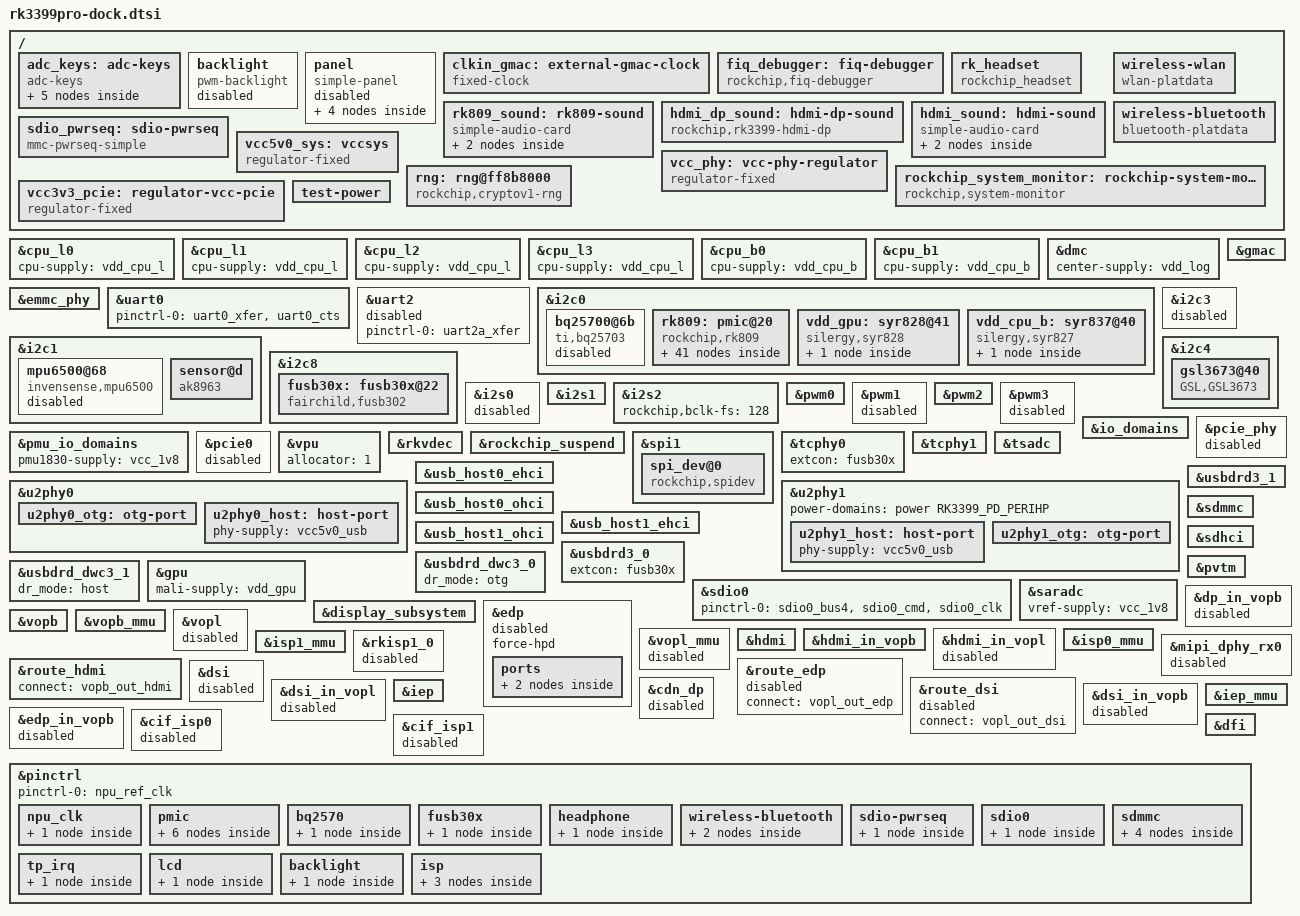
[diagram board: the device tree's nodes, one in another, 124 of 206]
// SPDX-License-Identifier: (GPL-2.0+ OR MIT)
// Copyright (c) 2018 Fuzhou Rockchip Electronics Co., Ltd

#include <dt-bindings/gpio/gpio.h>
#include <dt-bindings/pinctrl/rockchip.h>
#include <dt-bindings/input/input.h>
#include <dt-bindings/display/drm_mipi_dsi.h>
#include <dt-bindings/sensor-dev.h>
#include <dt-bindings/pwm/pwm.h>
#include "rk3399-vop-clk-set.dtsi"

/ {

	adc_keys: adc-keys {
		compatible = "adc-keys";
		io-channels = <&saradc 2>;
		io-channel-names = "buttons";
		poll-interval = <100>;
		keyup-threshold-microvolt = <1800000>;

		esc-key {
			linux,code = <KEY_ESC>;
			label = "esc";
			press-threshold-microvolt = <1310000>;
		};

		menu-key {
			linux,code = <KEY_MENU>;
			label = "menu";
			press-threshold-microvolt = <987000>;
		};

		home-key {
			linux,code = <KEY_HOME>;
			label = "home";
			press-threshold-microvolt = <624000>;
		};

		vol-down-key {
			linux,code = <KEY_VOLUMEDOWN>;
			label = "volume down";
			press-threshold-microvolt = <300000>;
		};

		vol-up-key {
			linux,code = <KEY_VOLUMEUP>;
			label = "volume up";
			press-threshold-microvolt = <17000>;
		};
	};

	backlight: backlight {
		status = "disabled";
		compatible = "pwm-backlight";
		pwms = <&pwm0 0 25000 0>;
		brightness-levels = <
			  0  20  20  21  21  22  22  23
			 23  24  24  25  25  26  26  27
			 27  28  28  29  29  30  30  31
			 31  32  32  33  33  34  34  35
			 35  36  36  37  37  38  38  39
			 40  41  42  43  44  45  46  47
			 48  49  50  51  52  53  54  55
			 56  57  58  59  60  61  62  63
			 64  65  66  67  68  69  70  71
			 72  73  74  75  76  77  78  79
			 80  81  82  83  84  85  86  87
			 88  89  90  91  92  93  94  95
			 96  97  98  99 100 101 102 103
			104 105 106 107 108 109 110 111
			112 113 114 115 116 117 118 119
			120 121 122 123 124 125 126 127
			128 129 130 131 132 133 134 135
			136 137 138 139 140 141 142 143
			144 145 146 147 148 149 150 151
			152 153 154 155 156 157 158 159
			160 161 162 163 164 165 166 167
			168 169 170 171 172 173 174 175
			176 177 178 179 180 181 182 183
			184 185 186 187 188 189 190 191
			192 193 194 195 196 197 198 199
			200 201 202 203 204 205 206 207
			208 209 210 211 212 213 214 215
			216 217 218 219 220 221 222 223
			224 225 226 227 228 229 230 231
			232 233 234 235 236 237 238 239
			240 241 242 243 244 245 246 247
			248 249 250 251 252 253 254 255
		>;
		default-brightness-level = <10>;
		pinctrl-names = "default";
		pinctrl-0 = <&bl_en>;
		enable-gpios = <&gpio1 RK_PB5 GPIO_ACTIVE_HIGH>;
	};

	panel: panel {
		status = "disabled";
		compatible = "simple-panel";
		backlight = <&backlight>;
		enable-gpios = <&gpio4 RK_PD6 GPIO_ACTIVE_HIGH>;
		prepare-delay-ms = <20>;
		enable-delay-ms = <20>;
		reset-delay-ms = <20>;

		display-timings {
			native-mode = <&timing0>;
			timing0: timing0 {
				clock-frequency = <65000000>;
				hactive = <1280>;
				vactive = <800>;
				hfront-porch = <28>;
				hsync-len = <16>;
				hback-porch = <16>;
				vfront-porch = <6>;
				vsync-len = <2>;
				vback-porch = <4>;
				hsync-active = <0>;
				vsync-active = <0>;
				de-active = <0>;
				pixelclk-active = <0>;
			};
		};

		ports {
			panel_in: endpoint {
				remote-endpoint = <&edp_out>;
			};
		};
	};

	clkin_gmac: external-gmac-clock {
		compatible = "fixed-clock";
		clock-frequency = <125000000>;
		clock-output-names = "clkin_gmac";
		#clock-cells = <0>;
	};

	fiq_debugger: fiq-debugger {
		compatible = "rockchip,fiq-debugger";
		rockchip,serial-id = <2>;
		rockchip,wake-irq = <0>;
		rockchip,irq-mode-enable = <1>;  /* If enable uart uses irq instead of fiq */
		rockchip,baudrate = <1500000>;  /* Only 115200 and 1500000 */
		pinctrl-names = "default";
		pinctrl-0 = <&uart2a_xfer>;
		interrupts = <GIC_SPI 150 IRQ_TYPE_LEVEL_HIGH 0>;
		status = "okay";
	};

	rk_headset {
		status = "okay";
		compatible = "rockchip_headset";
		headset_gpio = <&gpio0 RK_PB5 GPIO_ACTIVE_LOW>;	
		pinctrl-names = "default";
		pinctrl-0 = <&hp_det>;
		io-channels = <&saradc 3>;
	};

	rk809_sound: rk809-sound {
		compatible = "simple-audio-card";
		simple-audio-card,format = "i2s";
		simple-audio-card,name = "rockchip,rk809-codec";
		simple-audio-card,mclk-fs = <256>;
		simple-audio-card,widgets =
			"Microphone", "Mic Jack",
			"Headphone", "Headphone Jack";
		simple-audio-card,routing =
			"Mic Jack", "MICBIAS1",
			"IN1P", "Mic Jack",
			"Headphone Jack", "HPOL",
			"Headphone Jack", "HPOR";
		simple-audio-card,cpu {
			sound-dai = <&i2s1>;
		};
		simple-audio-card,codec {
			sound-dai = <&rk809_codec>;
		};
	};

	hdmi_dp_sound: hdmi-dp-sound {
		compatible = "rockchip,rk3399-hdmi-dp";
		rockchip,codec = <&hdmi &cdn_dp>;
		rockchip,cpu = <&i2s2>;
		status = "okay";
	};

	hdmi_sound: hdmi-sound {
		status = "okay";
		compatible = "simple-audio-card";
		simple-audio-card,format = "i2s";
		simple-audio-card,mclk-fs = <256>;
		simple-audio-card,name = "HDMI-CODEC";

		simple-audio-card,cpu {
			sound-dai = <&i2s2>;
		};

		simple-audio-card,codec {
			sound-dai = <&hdmi>;
		};
	};

	wireless-wlan {
		WIFI,host_wake_irq = <&gpio0 RK_PA3 GPIO_ACTIVE_HIGH>;
		compatible = "wlan-platdata";
		rockchip,grf = <&grf>;
		sdio_vref = <1800>;
		status = "okay";
		wifi_chip_type = "ap6354";
	};

	wireless-bluetooth {
		BT,reset_gpio = <&gpio2 RK_PD4 GPIO_ACTIVE_HIGH>;
		BT,wake_gpio = <&gpio2 RK_PD2 GPIO_ACTIVE_HIGH>;
		BT,wake_host_irq = <&gpio0 RK_PA5 GPIO_ACTIVE_HIGH>;
		//BT,power_gpio = <&gpio2 RK_PD4 GPIO_ACTIVE_HIGH>;
		clock-names = "ext_clock";
		clocks = <&rk809 0x01>;
		compatible = "bluetooth-platdata";
		pinctrl-0 = <&uart0_rts &bt_irq_gpio>;
		//pinctrl-0 = <&uart0_rts>;
		pinctrl-1 = <&uart0_gpios>;
		pinctrl-names = "default","rts_gpio";
		status = "okay";
		uart_rts_gpios = <&gpio2 19 GPIO_ACTIVE_LOW>;
	};

	sdio_pwrseq: sdio-pwrseq {
		status = "okay";
		compatible = "mmc-pwrseq-simple";
		clocks = <&rk809 0x01>;
		clock-names = "ext_clock";
		pinctrl-names = "default";
		pinctrl-0 = <&wifi_enable_h>;
		reset-gpios = <&gpio2 RK_PD3 GPIO_ACTIVE_LOW>;
	};

	vcc_phy: vcc-phy-regulator {
		compatible = "regulator-fixed";
		regulator-name = "vcc_phy";
		regulator-always-on;
		regulator-boot-on;
	};

	vcc5v0_sys: vccsys {
		compatible = "regulator-fixed";
		regulator-name = "vcc5v0_sys";
		regulator-always-on;
		regulator-boot-on;
		regulator-min-microvolt = <5000000>;
		regulator-max-microvolt = <5000000>;
	};

	rockchip_system_monitor: rockchip-system-monitor {
		compatible = "rockchip,system-monitor";
		rockchip,polling-delay = <200>;
		rockchip,thermal-zone = "soc-thermal";
	};

	vcc3v3_pcie: regulator-vcc-pcie {
		compatible = "regulator-fixed";
		enable-active-high;
		gpio = <&gpio4 RK_PD4 GPIO_ACTIVE_HIGH>;
		//pinctrl-names = "default";
		//pinctrl-0 = <&pcie_pwr>;
		regulator-name = "vcc3v3_pcie";
		regulator-always-on;
		regulator-boot-on;
		vin-supply = <&vcc5v0_sys>;
	};

	rng: rng@ff8b8000 {
		compatible = "rockchip,cryptov1-rng";
		reg = <0x0 0xff8b8000 0x0 0x1000>;
		clocks = <&cru SCLK_CRYPTO1>, <&cru HCLK_S_CRYPTO1>;
		clock-names = "clk_crypto", "hclk_crypto";
		assigned-clocks = <&cru SCLK_CRYPTO1>, <&cru HCLK_S_CRYPTO1>;
		assigned-clock-rates = <150000000>, <100000000>;
		status = "disabled";
	};

	test-power {
		status = "okay";
	};
};

&cpu_l0 {
	cpu-supply = <&vdd_cpu_l>;
};

&cpu_l1 {
	cpu-supply = <&vdd_cpu_l>;
};

&cpu_l2 {
	cpu-supply = <&vdd_cpu_l>;
};

&cpu_l3 {
	cpu-supply = <&vdd_cpu_l>;
};

&cpu_b0 {
	cpu-supply = <&vdd_cpu_b>;
};

&cpu_b1 {
	cpu-supply = <&vdd_cpu_b>;
};

&dmc {
	status = "okay";
	//pvtm = <&pvtm>;
	center-supply = <&vdd_log>;
};

&emmc_phy {
	status = "okay";
};

&gmac {
	assigned-clock-parents = <&clkin_gmac>;
	assigned-clocks = <&cru SCLK_RMII_SRC>;
	phy-supply = <&vcc_phy>;
	phy-mode = "rgmii";
	clock_in_out = "input";
	snps,reset-gpio = <&gpio3 RK_PB7 GPIO_ACTIVE_LOW>;
	snps,reset-active-low;
	snps,reset-delays-us = <0 10000 50000>;
	pinctrl-names = "default";
	pinctrl-0 = <&rgmii_pins>;
	tx_delay = <0x28>;
	rx_delay = <0x11>;
	status = "okay";
};

&uart0 {
	pinctrl-names = "default";
	pinctrl-0 = <&uart0_xfer &uart0_cts>;
	status = "okay";
};

&uart2 {
	pinctrl-0 = <&uart2a_xfer>;
	status = "disabled";
};

&i2c0 {
	status = "okay";
	i2c-scl-rising-time-ns = <180>;
	i2c-scl-falling-time-ns = <30>;
	clock-frequency = <400000>;

	bq25700@6b {
		compatible = "ti,bq25703";
		extcon = <&fusb30x>;
		//interrupt-parent = <0x33>;
		//interrupts = <0x01 0x08>;
		pd-charge-only = <0x00>;
		pinctrl-0 = <&charger_ok_int>;
		pinctrl-names = "default";
		reg = <0x6b>;
		status = "disabled";
		ti,charge-current = <0x16e360>;
		ti,input-current = <0x7a120>;
		ti,input-current-cdp = <0x1e8480>;
		ti,input-current-dc = <0x1e8480>;
		ti,input-current-dcp = <0x1e8480>;
		ti,input-current-sdp = <0x7a120>;
		ti,max-charge-voltage = <0x84d000>;
		ti,max-input-current = <0x5b8d80>;
		ti,max-input-voltage = <0x1312d00>;
		ti,minimum-sys-voltage = <0x663be0>;
		ti,otg-current = <0x7a120>;
		ti,otg-voltage = <0x4c4b40>;
	};

	rk809: pmic@20 {
		compatible = "rockchip,rk809";
		reg = <0x20>;

		interrupt-parent = <&gpio1>;
		interrupts = <RK_PC2 IRQ_TYPE_LEVEL_LOW>;
		pinctrl-names = "default", "pmic-sleep",
				"pmic-power-off", "pmic-reset";
		pinctrl-0 = <&pmic_int_l>;
		pinctrl-1 = <&soc_slppin_slp>, <&rk809_slppin_slp>;
		pinctrl-2 = <&soc_slppin_gpio>, <&rk809_slppin_pwrdn>;
		pinctrl-3 = <&soc_slppin_gpio>, <&rk809_slppin_null>;
		rockchip,system-power-controller;
		pmic-reset-func = <0>;
		wakeup-source;
		#clock-cells = <1>;
		clock-output-names = "rk808-clkout1", "rk808-clkout2";

		vcc1-supply = <&vcc5v0_sys>;
		vcc2-supply = <&vcc5v0_sys>;
		vcc3-supply = <&vcc5v0_sys>;
		vcc4-supply = <&vcc5v0_sys>;
		vcc5-supply = <&vcc_buck5>;
		vcc6-supply = <&vcc_buck5>;
		vcc7-supply = <&vcc3v3_sys>;
		vcc8-supply = <&vcc3v3_sys>;
		vcc9-supply = <&vcc5v0_sys>;

		pwrkey {
			status = "okay";
		};

		rk809_rtc: rtc {
			status = "okay";
		};

		pinctrl_rk8xx: pinctrl_rk8xx {
			gpio-controller;
			#gpio-cells = <2>;

			rk809_slppin_null: rk809_slppin_null {
				pins = "gpio_slp";
				function = "pin_fun0";
			};

			rk809_slppin_slp: rk809_slppin_slp {
				pins = "gpio_slp";
				function = "pin_fun1";
			};

			rk809_slppin_pwrdn: rk809_slppin_pwrdn {
				pins = "gpio_slp";
				function = "pin_fun2";
			};

			rk809_slppin_rst: rk809_slppin_rst {
				pins = "gpio_slp";
				function = "pin_fun3";
			};
		};

		regulators {
			vdd_log: DCDC_REG1 {
				regulator-always-on;
				regulator-boot-on;
				regulator-min-microvolt = <750000>;
				regulator-max-microvolt = <1350000>;
				regulator-initial-mode = <2>;
				regulator-name = "vdd_log";
				regulator-state-mem {
					regulator-off-in-suspend;
					regulator-suspend-microvolt = <900000>;
				};
			};

			vdd_cpu_l: DCDC_REG2 {
				regulator-always-on;
				regulator-boot-on;
				regulator-min-microvolt = <750000>;
				regulator-max-microvolt = <1350000>;
				regulator-ramp-delay = <6001>;
				regulator-initial-mode = <2>;
				regulator-name = "vdd_cpu_l";
				regulator-state-mem {
					regulator-off-in-suspend;
				};
			};

			vcc_ddr: DCDC_REG3 {
				regulator-always-on;
				regulator-boot-on;
				regulator-name = "vcc_ddr";
				regulator-initial-mode = <2>;
				regulator-state-mem {
					regulator-on-in-suspend;
				};
			};

			vcc3v3_sys: DCDC_REG4 {
				regulator-always-on;
				regulator-boot-on;
				regulator-min-microvolt = <3300000>;
				regulator-max-microvolt = <3300000>;
				regulator-initial-mode = <2>;
				regulator-name = "vcc3v3_sys";
				regulator-state-mem {
					regulator-on-in-suspend;
					regulator-suspend-microvolt = <3300000>;
				};
			};

			vcc_buck5: DCDC_REG5 {
				regulator-always-on;
				regulator-boot-on;
				regulator-min-microvolt = <2200000>;
				regulator-max-microvolt = <2200000>;
				regulator-name = "vcc_buck5";
				regulator-state-mem {
					regulator-on-in-suspend;
					regulator-suspend-microvolt = <2200000>;
				};
			};

			vcca_0v9: LDO_REG1 {
				regulator-always-on;
				regulator-boot-on;
				regulator-min-microvolt = <900000>;
				regulator-max-microvolt = <900000>;
				regulator-name = "vcca_0v9";
				regulator-state-mem {
					regulator-off-in-suspend;
				};
			};

			vcc_1v8: LDO_REG2 {
				regulator-always-on;
				regulator-boot-on;
				regulator-min-microvolt = <1800000>;
				regulator-max-microvolt = <1800000>;

				regulator-name = "vcc_1v8";
				regulator-state-mem {
					regulator-on-in-suspend;
					regulator-suspend-microvolt = <1800000>;
				};
			};

			vcc0v9_soc: LDO_REG3 {
				regulator-always-on;
				regulator-boot-on;
				regulator-min-microvolt = <900000>;
				regulator-max-microvolt = <900000>;

				regulator-name = "vcc0v9_soc";
				regulator-state-mem {
					regulator-on-in-suspend;
					regulator-suspend-microvolt = <900000>;
				};
			};

			vcca_1v8: LDO_REG4 {
				regulator-always-on;
				regulator-boot-on;
				regulator-min-microvolt = <1800000>;
				regulator-max-microvolt = <1800000>;

				regulator-name = "vcca_1v8";
				regulator-state-mem {
					regulator-off-in-suspend;
				};
			};

			vdd1v5_dvp: LDO_REG5 {
				regulator-always-on;
				regulator-boot-on;
				regulator-min-microvolt = <1500000>;
				regulator-max-microvolt = <1500000>;

				regulator-name = "vdd1v5_dvp";
				regulator-state-mem {
					regulator-off-in-suspend;
				};
			};

			vcc_1v5: LDO_REG6 {
				regulator-always-on;
				regulator-boot-on;
				regulator-min-microvolt = <1500000>;
				regulator-max-microvolt = <1500000>;

				regulator-name = "vcc_1v5";
				regulator-state-mem {
					regulator-off-in-suspend;
				};
			};

			vcc_3v0: LDO_REG7 {
				regulator-always-on;
				regulator-boot-on;
				regulator-min-microvolt = <3000000>;
				regulator-max-microvolt = <3000000>;

				regulator-name = "vcc_3v0";
				regulator-state-mem {
					regulator-off-in-suspend;
				};
			};

			vccio_sd: LDO_REG8 {
				regulator-always-on;
				regulator-boot-on;
				regulator-min-microvolt = <1800000>;
				regulator-max-microvolt = <3300000>;

				regulator-name = "vccio_sd";
				regulator-state-mem {
					regulator-off-in-suspend;
				};
			};

			vcc_sd: LDO_REG9 {
				regulator-always-on;
				regulator-boot-on;
				regulator-min-microvolt = <3300000>;
				regulator-max-microvolt = <3300000>;

				regulator-name = "vcc_sd";
				regulator-state-mem {
					regulator-off-in-suspend;
				};
			};

			vcc5v0_usb: SWITCH_REG1 {
				regulator-min-microvolt = <5000000>;
				regulator-max-microvolt = <5000000>;
				regulator-always-on;
				regulator-boot-on;
				regulator-name = "vcc5v0_usb";
				regulator-state-mem {
					regulator-on-in-suspend;
					regulator-suspend-microvolt = <5000000>;
				};
			};

			vccio_3v3: SWITCH_REG2 {
				regulator-always-on;
				regulator-boot-on;
				regulator-min-microvolt = <3300000>;
				regulator-max-microvolt = <3300000>;

				regulator-name = "vccio_3v3";
				regulator-state-mem {
					regulator-off-in-suspend;
				};
			};
		};

		rk809_codec: codec {
			#sound-dai-cells = <0>;
			compatible = "rockchip,rk809-codec", "rockchip,rk817-codec";
			clocks = <&cru SCLK_I2S_8CH_OUT>;
			clock-names = "mclk";
			pinctrl-names = "default";
			pinctrl-0 = <&i2s_8ch_mclk>;
			hp-volume = <20>;
			spk-volume = <3>;
			capture-volume = <0>;
			//mic-in-differential;
			status = "okay";
		};
	};

	vdd_gpu: syr828@41 {
		compatible = "silergy,syr828";
		fcs,suspend-voltage-selector = <1>;
		//phandle = <0xa4>;
		pinctrl-0 = <&vsel2_gpio>;
		reg = <0x41>;
		regulator-always-on;
		regulator-boot-on;
		regulator-compatible = "fan53555-reg";
		regulator-max-microvolt = <1400000>;
		regulator-min-microvolt = <735000>;
		regulator-name = "vdd_gpu";
		regulator-ramp-delay = <1000>;
		status = "okay";
		vin-supply = <&vcc5v0_sys>;
		vsel-gpios = <&gpio1 RK_PB6 GPIO_ACTIVE_HIGH>;

		regulator-state-mem {
			regulator-off-in-suspend;
		};
	};

	vdd_cpu_b: syr837@40 {
		compatible = "silergy,syr827";
		fcs,suspend-voltage-selector = <1>;
		//phandle = <0x12>;
		pinctrl-0 = <&vsel1_gpio>;
		reg = <0x40>;
		regulator-always-on;
		regulator-boot-on;
		regulator-compatible = "fan53555-reg";
		regulator-initial-state = <3>;
		regulator-max-microvolt = <1500000>;
		regulator-min-microvolt = <712500>;
		regulator-name = "vdd_cpu_b";
		regulator-ramp-delay = <1000>;
		vin-supply = <&vcc5v0_sys>;
		vsel-gpios = <&gpio1 RK_PC1 GPIO_ACTIVE_HIGH>;

		regulator-state-mem {
			regulator-off-in-suspend;
		};
	};
};

&i2c1 {
	status = "okay";
	i2c-scl-rising-time-ns = <140>;
	i2c-scl-falling-time-ns = <30>;	
	mpu6500@68 {
		status = "disabled";
		compatible = "invensense,mpu6500";
		reg = <0x68>;
		irq-gpio = <&gpio3 RK_PD2 IRQ_TYPE_EDGE_RISING>;
		mpu-int_config = <0x10>;
		mpu-level_shifter = <0>;
		mpu-orientation = <0 1 0 1 0 0 0 0 1>;
		orientation-x= <0>;
		orientation-y= <0>;
		orientation-z= <1>;
		mpu-debug = <1>;
	};

	sensor@d {
		status = "okay";
		compatible = "ak8963";
		reg = <0x0d>;
		type = <SENSOR_TYPE_COMPASS>;
		irq-gpio = <&gpio3 RK_PD7 IRQ_TYPE_EDGE_RISING>;
		irq_enable = <0>;
		poll_delay_ms = <30>;
		layout = <3>;
	};
};

&i2c3 {
	i2c-scl-rising-time-ns = <450>;
	i2c-scl-falling-time-ns = <15>;
	status = "disabled";
};

&i2c4 {
	status = "okay";
	i2c-scl-falling-time-ns = <11>;
	i2c-scl-rising-time-ns = <345>;
	gsl3673@40 {
		compatible = "GSL,GSL3673";
		irq_gpio_number = <&gpio4 19 8>;
		reg = <0x40>;
		rst_gpio_number = <&gpio4 22 GPIO_ACTIVE_HIGH>;
		screen_max_x = <0x600>;
		screen_max_y = <0x800>;
	};
};

&i2c8 {
	status = "okay";
	i2c-scl-falling-time-ns = <11>;
	i2c-scl-rising-time-ns = <345>;
	clock-frequency = <100000>;
	status = "okay";

	fusb30x: fusb30x@22 {
		compatible = "fairchild,fusb302";
		int-n-gpios = <&gpio1 0x02 0x00>;
		//phandle = <0x28>;
		pinctrl-0 = <&fusb0_int>;
		pinctrl-names = "default";
		reg = <0x22>;
		status = "okay";
		//fusb302,role = "ROLE_MODE_DRP";
		//fusb302,try_role = "ROLE_MODE_DFP";
	};
	
};

&i2s0 {
	#sound-dai-cells = <0>;
	status = "dsiabled";
};

&i2s1 {
	status = "okay";
	#sound-dai-cells = <0>;
};
&i2s2 {
	#sound-dai-cells = <0>;
	rockchip,bclk-fs = <128>;
	status = "okay";
};

&pwm0 {
	status = "okay";
};

&pwm1 {
	status = "disabled";
};

&pwm2 {
	status = "okay";
};

&pwm3 {
	status = "disabled";
};

&io_domains {
	status = "okay";
	bt656-supply = <&vcca_1v8>;
	audio-supply = <&vcca_1v8>;
	sdmmc-supply = <&vccio_sd>;
	gpio1830-supply = <&vcc_3v0>;
};

&pmu_io_domains {
	status = "okay";
	pmu1830-supply = <&vcc_1v8>;
};

&pcie_phy {
	status = "disabled";
};

&pcie0 {
	status = "disabled";
	vpcie0v9-supply = <&vcca_0v9>;	/* VCC_0V9_S0 */
	vpcie1v8-supply = <&vcca_1v8>;	/* VCC_1V8_S0 */
	vpcie3v3-supply = <&vcc3v3_pcie>;
};

&vpu {
	status = "okay";
	allocator = <1>;
	//vcodec-supply = <&vdd_log>;
	/* 0 means ion, 1 means drm */
	//allocator = <0>;
};

&rkvdec {
	status = "okay";
	//vcodec-supply = <&vdd_log>;
	/* 0 means ion, 1 means drm */
	//allocator = <0>;
};

&rockchip_suspend {
	status = "okay";
	rockchip,sleep-debug-en = <1>;
	rockchip,sleep-mode-config = <
		(0
		| RKPM_SLP_ARMPD
		| RKPM_SLP_PERILPPD
		| RKPM_SLP_DDR_RET
		| RKPM_SLP_PLLPD
		| RKPM_SLP_CENTER_PD
		| RKPM_SLP_OSC_DIS
		| RKPM_SLP_AP_PWROFF
		)
	>;
	rockchip,wakeup-config = <
		(0
		| RKPM_GPIO_WKUP_EN
		| RKPM_USB_WKUP_EN
		| RKPM_USB_LINESTATE_WKUP_EN
		)
	>;

	rockchip,pwm-regulator-config = <
		(0
		| PWM2_REGULATOR_EN
		)
	>;	
	rockchip,power-ctrl =
		<&gpio1 RK_PC1 GPIO_ACTIVE_HIGH>,
		<&gpio1 RK_PB6 GPIO_ACTIVE_HIGH>;
};

&spi1 {
	status = "okay";
	dma-names = "tx", "rx";
	dmas = <&dmac_peri 12>, <&dmac_peri 13>;
	max-freq = <48000000>; /* spi internal clk, don't modify */
	spi_dev@0 {
		compatible = "rockchip,spidev";
		reg = <0>;
		spi-max-frequency = <12000000>;
		spi-lsb-first;
		status = "okay";
	};
};

&tcphy0 {
	extcon = <&fusb30x>;
	status = "okay";
};

&tcphy1 {
	status = "okay";
};

&tsadc {
	rockchip,hw-tshut-mode = <1>; /* tshut mode 0:CRU 1:GPIO */
	rockchip,hw-tshut-polarity = <1>; /* tshut polarity 0:LOW 1:HIGH */
	rockchip,hw-tshut-temp = <120000>;
	status = "okay";
};

&u2phy0 {
	status = "okay";
	extcon = <&fusb30x>;
	power-domains = <&power RK3399_PD_PERIHP>;
	u2phy0_otg: otg-port {
		status = "okay";
	};

	u2phy0_host: host-port {
		phy-supply = <&vcc5v0_usb>;
		status = "okay";
	};
};

&u2phy1 {
	status = "okay";
	power-domains = <&power RK3399_PD_PERIHP>;
	u2phy1_host: host-port {
		phy-supply = <&vcc5v0_usb>;
		status = "okay";
	};

	u2phy1_otg: otg-port {
		status = "okay";
	};
};

&usb_host0_ehci {
	status = "okay";
};

&usb_host0_ohci {
	status = "okay";
};

&usb_host1_ehci {
	status = "okay";
};

&usb_host1_ohci {
	status = "okay";
};

&usbdrd3_0 {
	extcon = <&fusb30x>;
	status = "okay";
};

&usbdrd_dwc3_0 {
	dr_mode = "otg";
	status = "okay";
};

&usbdrd3_1 {
	status = "okay";
};

&usbdrd_dwc3_1 {
	dr_mode = "host";
	status = "okay";
};

&sdio0 {
	status = "okay";
	pinctrl-0 = <&sdio0_bus4 &sdio0_cmd &sdio0_clk>;
};

&sdmmc {
	status = "okay";
	sd-uhs-sdr12;
	sd-uhs-sdr25;
	sd-uhs-sdr50;
	sd-uhs-sdr104;
	//vmmc-supply = <&vcc_sd>
};

&sdhci {
	status = "okay";
};

&gpu {
	status = "okay";
	mali-supply = <&vdd_gpu>;
};

&vpu {
	status = "okay";
	/* 0 means ion, 1 means drm */
	//allocator = <0>;
};

&pvtm {
	status = "okay";
};
/*
&power {
	pd_vi-supply = <&vdd_log>;
	pd_vpu-supply = <&vdd_log>;
	pd_gpu-supply = <&vdd_log>;
	pd_usb-supply = <&vcc5v0_usb>;
	pd_vo-supply = <&vdd_log>;
	pd_vopb-supply = <&vdd_log>;
	pd_vopl-supply = <&vdd_log>;
};
 */

&saradc {
	status = "okay";
	vref-supply = <&vcc_1v8>;
};

&display_subsystem {
	status = "okay";
};

&dp_in_vopb {
	status = "disabled";
};

&edp {
	status = "disabled";
	force-hpd;
	ports {
		port@1 {
			reg = <1>;
			edp_out: endpoint {
				remote-endpoint = <&panel_in>;
			};
		};
	};
};

&vopb {
	status = "okay";
	assigned-clocks = <&cru DCLK_VOP0_DIV>;
	assigned-clock-parents = <&cru PLL_VPLL>;
	rockchip,grf = <&grf>;
};

&vopb_mmu {
	status = "okay";
};

&vopl {
	status = "disabled";
	assigned-clocks = <&cru DCLK_VOP1_DIV>;
	assigned-clock-parents = <&cru PLL_CPLL>;
	rockchip,grf = <&grf>;
};

&vopl_mmu {
	status = "disabled";
};

&hdmi {
	status = "okay";
	#address-cells = <1>;
	#size-cells = <0>;
	#sound-dai-cells = <0>;
	//ddc-i2c-bus = <&i2c3>;
	pinctrl-0 = <&hdmi_i2c_xfer &hdmi_cec>;
	ddc-i2c-scl-high-time-ns = <9625>;
	ddc-i2c-scl-low-time-ns = <10000>;
	rockchip,phy-table =
		<74250000  0x8009 0x0004 0x0272>,
		<165000000 0x802b 0x0004 0x0209>,
		<297000000 0x8039 0x0005 0x028d>,
		<594000000 0x8039 0x0000 0x00f6>,
		<000000000 0x0000 0x0000 0x0000>;
};

&hdmi_in_vopb {
	status = "okay";
};

&hdmi_in_vopl {
	status = "disabled";
};

&isp0_mmu {
	status = "okay";
};

&isp1_mmu {
	status = "okay";
};


&rkisp1_0 {
	status = "disabled";
};

&mipi_dphy_rx0 {
	status = "disabled";
};

&route_hdmi {
	status = "okay";
	connect = <&vopb_out_hdmi>;
};

&route_edp {
	connect = <&vopl_out_edp>;
	status = "disabled";
};
&route_dsi {
	connect = <&vopl_out_dsi>;
	status = "disabled";
};

&dsi {
	status = "disabled";
};

&dsi_in_vopl {
	status = "disabled";
};

&dsi_in_vopb {
	status = "disabled";
};

&dp_in_vopb {
	status = "disabled";
};

&edp_in_vopb {
	status = "disabled";
};

&cdn_dp {
	extcon = <&fusb30x>;
	phys=<&tcphy0_dp>;
	status="disabled";
};

&iep {
	status="okay";
};
&iep_mmu {
	status="okay";
};

&cif_isp0 {
	assigned-clock-parents = <&cru 0x05>;
	assigned-clock-rates = <800000000>;
	assigned-clocks = <&cru 0xb2>;
	pinctrl-names = "cif_clkout\0isp_dvp8bit0\0isp_mipi_fl\0isp_mipi_fl_prefl\0isp_flash_as_gpio\0isp_flash_as_trigger_out";
	pinctrl-0 = <&cif_clkout>;
	pinctrl-1 = <&cif_clkout &isp_dvp_d0d7>;
	pinctrl-2 = <&cif_clkout>;
	pinctrl-3 = <&cif_clkout &isp_prelight >;
	pinctrl-4 = <&isp_flash_trigger_as_gpio>;
	pinctrl-5 = <&isp_flash_trigger>;
	rockchip,cru = <&cru>;
	rockchip,gpios = <&gpio1 3 0>;
	rockchip,grf = <&grf>;
	//rockchip,isp,cifphy = <0x01>;
	//rockchip,isp,dsiphy,reg = <0xff968000 0x8000>;
	//rockchip,isp,iommu-enable = <1>;
	//rockchip,isp,mipiphy = <0x02>;
	status = "disabled";
};

&cif_isp1 {
	pinctrl-0 = <&cif_clkout>;
	pinctrl-1 = <&cif_clkout  &isp_dvp_d0d7>;
	pinctrl-2 = <&cif_clkout>;
	pinctrl-3 = <&isp_prelight>;
	pinctrl-4 = <&isp_flash_trigger_as_gpio>;
	pinctrl-5 = <&isp_flash_trigger>;
	pinctrl-names = "cif_clkout\0isp_dvp8bit0\0isp_mipi_fl\0isp_mipi_fl_prefl\0isp_flash_as_gpio\0isp_flash_as_trigger_out";
	rockchip,cru = <&cru>;
	rockchip,gpios = <&gpio1 3 0>;
	rockchip,grf = <&grf>;
	//rockchip,isp,cifphy = <0x01>;
	//rockchip,isp,dsiphy,reg = <0xff968000 0x8000>;
	//rockchip,isp,iommu-enable = <0x01>;
	//rockchip,isp,mipiphy = <0x02>;
	status = "disabled";
};

&dfi {
	status = "okay";
};

&rng {
	status = "okay";
};

&pinctrl {
	pinctrl-names = "default";
	pinctrl-0 = <&npu_ref_clk>;

	npu_clk {
		npu_ref_clk: npu-ref-clk {
		     rockchip,pins =
			     <0 RK_PA2 1 &pcfg_pull_none>;
	     };
	};

	pmic {
		pmic_int_l: pmic-int-l {
			rockchip,pins =
				<1 RK_PC2 0 &pcfg_pull_up>;
		};
		vsel1_gpio: vsel1-gpio {
			rockchip,pins =
				<1 RK_PC1 0 &pcfg_pull_down>;
		};
		vsel2_gpio: vsel2-gpio {
			rockchip,pins =
				<1 RK_PB6 0 &pcfg_pull_down>;
		};

		soc_slppin_gpio: soc-slppin-gpio {
			rockchip,pins =
				<1 RK_PA5 0 &pcfg_output_low>;
		};

		soc_slppin_slp: soc-slppin-slp {
			rockchip,pins =
				<1 RK_PA5 1 &pcfg_pull_down>;
		};

		soc_slppin_rst: soc-slppin-rst {
			rockchip,pins =
				<1 RK_PA5 2 &pcfg_pull_none>;
		};
	};

	bq2570 {
		charger_ok_int: charger-ok-int {
			rockchip,pins =
				<1 RK_PA1 0 &pcfg_pull_up>;
			};
	};

	fusb30x {
		fusb0_int: fusb0-int {
			rockchip,pins =
				<1 RK_PA2 0 &pcfg_pull_up>;
			};
	};
	
	headphone {
		hp_det: hp-det {
			rockchip,pins =
				<0 RK_PB5 0 &pcfg_pull_up>;
		};
	};

	wireless-bluetooth {
		bt_irq_gpio: bt-irq-gpio {
			//phandle = <0xe7>;
			rockchip,pins = <0 RK_PA5 RK_FUNC_GPIO &pcfg_pull_down>;
		};
		uart0_gpios: uart0-gpios {
			rockchip,pins =
				<2 RK_PC3 RK_FUNC_GPIO &pcfg_pull_none>;
		};
	};

	sdio-pwrseq {
		wifi_enable_h: wifi-enable-h {
			rockchip,pins =
				<2 RK_PD3 0 &pcfg_pull_none>;
		};
	};

	sdio0 {
		sdio0_bus4: sdio0-bus4 {
			rockchip,pins =
				<2 20 RK_FUNC_1 &pcfg_pull_up>,
				<2 21 RK_FUNC_1 &pcfg_pull_up>,
				<2 22 RK_FUNC_1 &pcfg_pull_up>,
				<2 23 RK_FUNC_1 &pcfg_pull_up>;
		};
	};

	sdmmc {
		sdmmc_bus1: sdmmc-bus1 {
			rockchip,pins =
				<4 8 RK_FUNC_1 &pcfg_pull_up_10ma>;
		};

		sdmmc_bus4: sdmmc-bus4 {
			rockchip,pins =
				<4 8 RK_FUNC_1 &pcfg_pull_up_10ma>,
				<4 9 RK_FUNC_1 &pcfg_pull_up_10ma>,
				<4 10 RK_FUNC_1 &pcfg_pull_up_10ma>,
				<4 11 RK_FUNC_1 &pcfg_pull_up_10ma>;
		};

		sdmmc_clk: sdmmc-clk {
			rockchip,pins =
				<4 12 RK_FUNC_1 &pcfg_pull_none_10ma>;
		};

		sdmmc_cmd: sdmmc-cmd {
			rockchip,pins =
				<4 13 RK_FUNC_1 &pcfg_pull_up_10ma>;
		};
	};

	tp_irq {
		tp_irq_gpio: tp-irq-gpio {
			rockchip,pins =
				<3 RK_PB0 0 &pcfg_pull_up>;
		};
	};
	
	lcd {
		lcd_rst_gpio: lcd-rst-gpio {
			rockchip,pins =
				<3 4 RK_FUNC_GPIO &pcfg_pull_none>;// eDP
		};
	};

	backlight {
		bl_en: bl-en {
			rockchip,pins =
				<1 13 RK_FUNC_GPIO &pcfg_pull_none>;// eDP
		};
	};

	isp {
		isp_dvp_d0d7: isp-dvp-d0d7 {
			phandle = <0xd1>;
			rockchip,pins = <0x02 0x00 0x03 0xc7 0x02 0x01 0x03 0xc7 0x02 0x02 0x03 0xc7 0x02 0x03 0x03 0xc7 0x02 0x04 0x03 0xc7 0x02 0x05 0x03 0xc7 0x02 0x06 0x03 0xc7 0x02 0x07 0x03 0xc7 0x02 0x08 0x03 0xc7 0x02 0x09 0x03 0xc7 0x02 0x0a 0x03 0xc7>;
		};
		isp_prelight: isp-prelight {
			rockchip,pins = <0x01 0x04 0x01 0xc7>;
		};
		isp_flash_trigger_as_gpio: isp-flash-trigger-as-gpio {
			rockchip,pins = <0x01 0x03 0x00 0xc7>;
		};
	};
};

/* DON'T PUT ANYTHING BELOW HERE.  PUT IT ABOVE PINCTRL */
/* DON'T PUT ANYTHING BELOW HERE.  PUT IT ABOVE PINCTRL */
/* DON'T PUT ANYTHING BELOW HERE.  PUT IT ABOVE PINCTRL */
